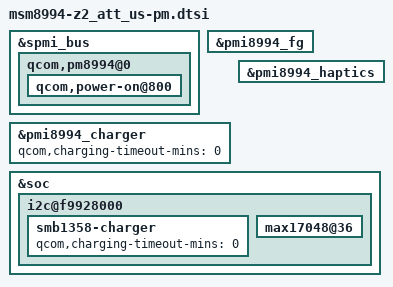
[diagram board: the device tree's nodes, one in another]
/* Copyright (c) 2014, The Linux Foundation. All rights reserved.
 *
 * This program is free software; you can redistribute it and/or modify
 * it under the terms of the GNU General Public License version 2 and
 * only version 2 as published by the Free Software Foundation.
 *
 * This program is distributed in the hope that it will be useful,
 * but WITHOUT ANY WARRANTY; without even the implied warranty of
 * MERCHANTABILITY or FITNESS FOR A PARTICULAR PURPOSE.  See the
 * GNU General Public License for more details.
 */

#include "../msm8994-z2_common/msm8994-common-pm.dtsi"

&spmi_bus {
	qcom,pm8994@0 {
		qcom,power-on@800 {
			status = "ok";
		};
	};
};

&pmi8994_fg {
	status = "ok";
};

&pmi8994_charger {
	status = "ok";
	qcom,charging-timeout-mins = <0>;
};

&pmi8994_haptics {
	status = "ok";
};

&soc {
	i2c@f9928000 { /* BLSP1 QUP6 */
		status = "ok";
		smb1358-charger{
			status = "ok";
			qcom,charging-timeout-mins = <0>;
		};

		max17048@36 {
			status = "ok";
		};
	};
};
